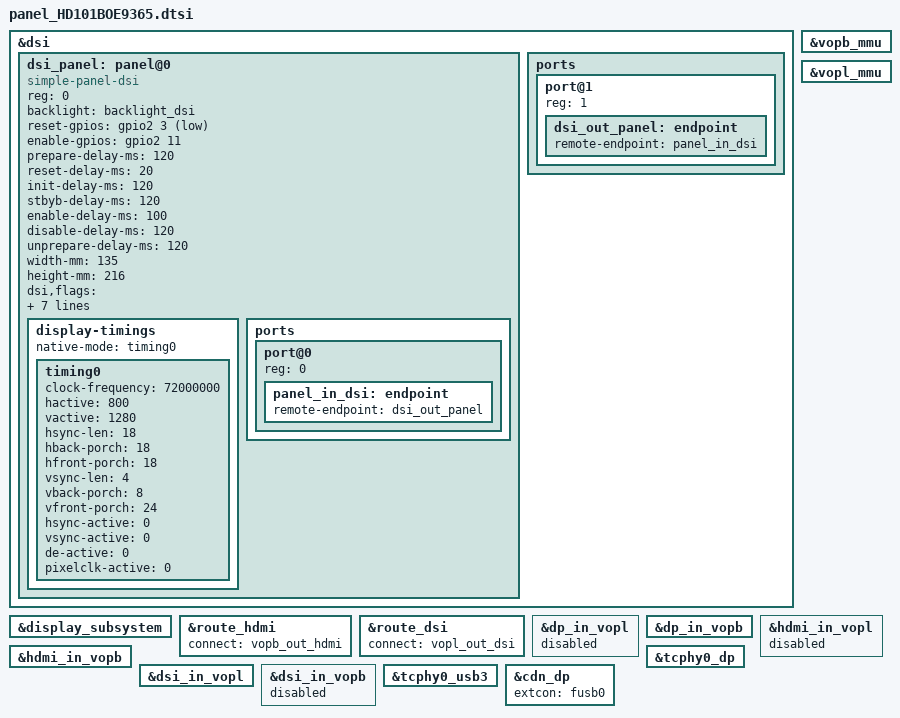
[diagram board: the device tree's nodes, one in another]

&dsi {
    status = "okay";
    dsi_panel: panel@0 {
                status = "okay";
                compatible = "simple-panel-dsi";
                reg = <0>;
                backlight = <&backlight_dsi>;
//                power-supply = <&vcc_lcd_dsi>;
                reset-gpios = <&gpio2 3 GPIO_ACTIVE_LOW>; // MIPI_RESET GPIO2_A3
                enable-gpios = <&gpio2 11 GPIO_ACTIVE_HIGH>; // GPIO2_B3
//                enable-gpios = <&gpio2 7 GPIO_ACTIVE_HIGH>; // GPIO2_A7

		prepare-delay-ms = <120>;
		reset-delay-ms = <20>;
		init-delay-ms = <120>;
		stbyb-delay-ms = <120>;
		enable-delay-ms = <100>;
		disable-delay-ms = <120>;
		unprepare-delay-ms = <120>;

		width-mm = <135>;
		height-mm = <216>;
		dsi,flags = <(MIPI_DSI_MODE_VIDEO | MIPI_DSI_MODE_VIDEO_BURST | MIPI_DSI_MODE_LPM | MIPI_DSI_MODE_EOT_PACKET)>;
        	dsi,format = <MIPI_DSI_FMT_RGB888>;
        	bus-format = <MEDIA_BUS_FMT_RBG888_1X24>;
//                dsi,flags = <(MIPI_DSI_MODE_VIDEO | MIPI_DSI_MODE_VIDEO_BURST)>;
//                dsi,format = <MIPI_DSI_FMT_RGB888>;
                dsi,lanes = <4>;

		panel-init-sequence = [
			15 00 02 E0 00     
			15 00 02 E1 93     
			15 00 02 E2 65     
			15 00 02 E3 F8     
			15 00 02 80 03    
			15 00 02 E0 01     
			15 00 02 00 00     
			15 00 02 01 2F      
			15 00 02 03 00     
			15 00 02 04 A0     
			15 00 02 17 00     
			15 00 02 18 AF     
			15 00 02 19 01     
			15 00 02 1A 00     
			15 00 02 1B AF     
			15 00 02 1C 01     
			15 00 02 1F 3E     
			15 00 02 20 28     
			15 00 02 21 28     
			15 00 02 22 7E     
			15 00 02 24 FE     
			15 00 02 35 26     
			15 00 02 37 09     
			15 00 02 38 04     
			15 00 02 39 00     
			15 00 02 3A 01     
			15 00 02 3C 7C     
			15 00 02 3D FF     
			15 00 02 3E FF     
			15 00 02 3F 7F     
			15 00 02 40 06     
			15 00 02 41 A0     
			15 00 02 42 81     
			15 00 02 43 08     
			15 00 02 44 0B     
			15 00 02 45 28     
			15 00 02 55 0F       
			15 00 02 57 69     
			15 00 02 59 0A     
			15 00 02 5A 28     
			15 00 02 5B 14     
			15 00 02 5D 7C                   
			15 00 02 5E 65           
			15 00 02 5F 55         
			15 00 02 60 47         
			15 00 02 61 43         
			15 00 02 62 32         
			15 00 02 63 34         
			15 00 02 64 1C         
			15 00 02 65 33         
			15 00 02 66 31         
			15 00 02 67 30         
			15 00 02 68 4E         
			15 00 02 69 3C         
			15 00 02 6A 44         
			15 00 02 6B 35         
			15 00 02 6C 31         
			15 00 02 6D 23         
			15 00 02 6E 11         
			15 00 02 6F 00         
			15 00 02 70 7C         
			15 00 02 71 65         
			15 00 02 72 55         
			15 00 02 73 47         
			15 00 02 74 43         
			15 00 02 75 32         
			15 00 02 76 34         
			15 00 02 77 1C         
			15 00 02 78 33         
			15 00 02 79 31         
			15 00 02 7A 30         
			15 00 02 7B 4E         
			15 00 02 7C 3C         
			15 00 02 7D 44         
			15 00 02 7E 35         
			15 00 02 7F 31         
			15 00 02 80 23         
			15 00 02 81 11         
			15 00 02 82 00        
			15 00 02 E0 02     
			15 00 02 00 1E     
			15 00 02 01 1E     
			15 00 02 02 41     
			15 00 02 03 41     
			15 00 02 04 43     
			15 00 02 05 43     
			15 00 02 06 1F     
			15 00 02 07 1F     
			15 00 02 08 1F     
			15 00 02 09 1F     
			15 00 02 0A 1E     
			15 00 02 0B 1E     
			15 00 02 0C 1F     
			15 00 02 0D 47     
			15 00 02 0E 47     
			15 00 02 0F 45     
			15 00 02 10 45     
			15 00 02 11 4B     
			15 00 02 12 4B     
			15 00 02 13 49     
			15 00 02 14 49     
			15 00 02 15 1F     
			15 00 02 16 1E     
			15 00 02 17 1E     
			15 00 02 18 40     
			15 00 02 19 40     
			15 00 02 1A 42     
			15 00 02 1B 42     
			15 00 02 1C 1F     
			15 00 02 1D 1F     
			15 00 02 1E 1F     
			15 00 02 1F 1F     
			15 00 02 20 1E     
			15 00 02 21 1E     
			15 00 02 22 1F     
			15 00 02 23 46     
			15 00 02 24 46     
			15 00 02 25 44     
			15 00 02 26 44     
			15 00 02 27 4A     
			15 00 02 28 4A     
			15 00 02 29 48     
			15 00 02 2A 48     
			15 00 02 2B 1F     
			15 00 02 2C 1F     
			15 00 02 2D 1F     
			15 00 02 2E 00     
			15 00 02 2F 00     
			15 00 02 30 00     
			15 00 02 31 00     
			15 00 02 32 1E     
			15 00 02 33 1E     
			15 00 02 34 35     
			15 00 02 35 1F     
			15 00 02 36 15     
			15 00 02 37 15     
			15 00 02 38 1F     
			15 00 02 39 08     
			15 00 02 3A 08     
			15 00 02 3B 0A     
			15 00 02 3C 0A     
			15 00 02 3D 04     
			15 00 02 3E 04     
			15 00 02 3F 06     
			15 00 02 40 06     
			15 00 02 41 1F     
			15 00 02 42 1F     
			15 00 02 43 1F     
			15 00 02 44 01     
			15 00 02 45 01     
			15 00 02 46 01     
			15 00 02 47 01     
			15 00 02 48 1E     
			15 00 02 49 1E     
			15 00 02 4A 35     
			15 00 02 4B 1F     
			15 00 02 4C 15     
			15 00 02 4D 15     
			15 00 02 4E 1F     
			15 00 02 4F 09     
			15 00 02 50 09     
			15 00 02 51 0B     
			15 00 02 52 0B     
			15 00 02 53 05     
			15 00 02 54 05     
			15 00 02 55 07     
			15 00 02 56 07     
			15 00 02 57 1F     
			15 00 02 58 40     
			15 00 02 5B 30     
			15 00 02 5C 03     
			15 00 02 5D 30     
			15 00 02 5E 01     
			15 00 02 5F 02     
			15 00 02 63 14     
			15 00 02 64 6A     
			15 00 02 67 73     
			15 00 02 68 05     
			15 00 02 69 14     
			15 00 02 6A 6A     
			15 00 02 6B 0C     
			15 00 02 6C 00     
			15 00 02 6D 00     
			15 00 02 6E 00     
			15 00 02 6F 88     
			15 00 02 E0 04     
			15 00 02 02 23    
			15 00 02 09 11     
			15 00 02 0E 48     
			15 00 02 36 49     
			15 00 02 2B 08     
			15 00 02 2E 03     
			15 00 02 E0 00     
			15 00 02 E6 02     
			15 00 02 E7 0C     
			15 78 02 11 00  	
			15 05 02 29 00 
			15 00 02 35 00  
		];

		panel-exit-sequence = [
			
		];


               display-timings {
                        native-mode = <&timing0>;
                        timing0: timing0 {
				clock-frequency = <72000000>;
				hactive = <800>;
				vactive = <1280>;

				hsync-len = <18>;
				hback-porch = <18>;
				hfront-porch = <18>;

				vsync-len = <4>;
				vback-porch = <8>;
				vfront-porch = <24>;

				hsync-active = <0>;
				vsync-active = <0>;
				de-active = <0>;
				pixelclk-active = <0>;
                         };
                 };

                ports {
                        #address-cells = <1>;
                        #size-cells = <0>;

                        port@0 {
                                reg = <0>;
                                panel_in_dsi: endpoint {
                                        remote-endpoint = <&dsi_out_panel>;
                                };
                        };
                };
         };

        ports {
                #address-cells = <1>;
                #size-cells = <0>;

                port@1 {
                        reg = <1>;
                        dsi_out_panel: endpoint {
                                remote-endpoint = <&panel_in_dsi>;
                        };
                };
        };
};

&display_subsystem {
        status = "okay";
};

&vopb_mmu {
        status = "okay";
};

&vopl_mmu {
        status = "okay";
};

&route_hdmi {
	status = "okay";
	connect = <&vopb_out_hdmi>;
};

&route_dsi {
	status = "okay";
	connect = <&vopl_out_dsi>;
};

&dp_in_vopl {
	status = "disabled";
};

&dp_in_vopb {
	status = "okay";
};

&hdmi_in_vopl {
	status = "disabled";
};

&hdmi_in_vopb {
	status = "okay";
};

&dsi_in_vopl {
	status = "okay";
};

&dsi_in_vopb {
	status = "disabled";
};

&tcphy0_dp {
	status = "okay";
};

&tcphy0_usb3 {
	status = "okay";
};

// Display Port ower USB-C
&cdn_dp {
	status = "okay";
	extcon = <&fusb0>;
};
